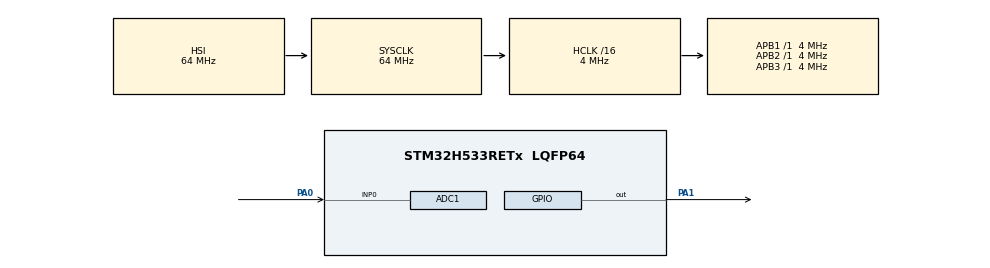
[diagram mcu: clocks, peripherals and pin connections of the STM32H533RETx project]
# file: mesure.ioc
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ADC1.Channel-0\#ChannelRegularConversion=ADC_CHANNEL_0
ADC1.ContinuousConvMode=ENABLE
ADC1.DMAContinuousRequests=ENABLE
ADC1.EOCSelection=ADC_EOC_SEQ_CONV
ADC1.MonitoredBy-0\#ChannelRegularConversion=__NULL
ADC1.NbrOfConversionFlag=1
ADC1.OffsetNumber-0\#ChannelRegularConversion=ADC_OFFSET_NONE
ADC1.Rank-0\#ChannelRegularConversion=1
ADC1.SamplingTime-0\#ChannelRegularConversion=ADC_SAMPLETIME_640CYCLES_5
ADC1.master=1
BOOTPATH.BootPathName=LEGACY
BOOTPATH.UserSelectedBootPath=LEGACY
CORTEX_M33_NS.userName=CORTEX_M33
GPDMA1.CIRCULARMODE_GPDMACH7=ENABLE
GPDMA1.DESTDATAWIDTH_GPDMACH7=DMA_DEST_DATAWIDTH_HALFWORD
GPDMA1.DESTINC_GPDMACH7=DMA_DINC_INCREMENTED
GPDMA1.IPHANDLE_GPDMACH7-SIMPLEREQUEST_GPDMACH7=__NULL
GPDMA1.REQUEST_GPDMACH7=GPDMA1_REQUEST_ADC1
GPDMA1.SRCDATAWIDTH_GPDMACH7=DMA_SRC_DATAWIDTH_HALFWORD
Mcu.Family=STM32H5
Mcu.Name=STM32H533RETx
Mcu.Package=LQFP64
NVIC.GPDMA1_Channel7_IRQn=true\:0\:0\:false\:false\:true\:false\:true\:true
NVIC.PriorityGroup=NVIC_PRIORITYGROUP_4
PA0.Signal=ADCx_INP0
PA1.GPIO_Speed=GPIO_SPEED_FREQ_VERY_HIGH
PA1.Signal=GPIO_Output
ProjectManager.HeapSize=0x200
ProjectManager.StackSize=0x400
ProjectManager.TargetToolchain=STM32CubeIDE
RCC.ADCFreq_Value=4000000
RCC.AHBCLKDivider=RCC_SYSCLK_DIV16
RCC.AHBFreq_Value=4000000
RCC.APB1Freq_Value=4000000
RCC.APB1TimFreq_Value=4000000
RCC.APB2Freq_Value=4000000
RCC.APB2TimFreq_Value=4000000
RCC.APB3Freq_Value=4000000
RCC.CSI_VALUE=4000000
RCC.CortexFreq_Value=4000000
RCC.EPOD_VALUE=4000000
RCC.HCLKFreq_Value=4000000
RCC.HSE_VALUE=25000000
RCC.HSI48_VALUE=48000000
RCC.HSIDiv=RCC_HSI_DIV1
RCC.HSI_VALUE=64000000
RCC.LSE_VALUE=32768
RCC.LSIRC_VALUE=32000
RCC.PLL2FRACN=0
RCC.PLL3FRACN=0
RCC.PLLFRACN=0
RCC.PLLN=90
RCC.SYSCLKFreq_VALUE=64000000
RCC.USBFreq_Value=48000000
RCC.VCOOutputFreq_Value=360000000
SH.ADCx_INP0.0=ADC1_INP0,IN0-Single-Ended
VP_BOOTPATH_VS_BOOTPATH.Mode=BP_Activate
VP_CORTEX_M33_NS_VS_Hclk.Mode=Hclk_Mode
VP_GPDMA1_VS_GPDMACH7.Mode=SIMPLEREQUEST_GPDMACH7
VP_MEMORYMAP_VS_MEMORYMAP.Mode=CurAppReg
VP_PWR_VS_LPOM.Mode=PowerOptimisation
VP_PWR_VS_SECSignals.Mode=Security/Privilege
board=NUCLEO-H533RE

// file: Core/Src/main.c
/* USER CODE BEGIN Header */
/**
  ******************************************************************************
  * @file           : main.c
  * @brief          : Main program body
  ******************************************************************************
  * @attention
  *
  * Copyright (c) 2025 STMicroelectronics.
  * All rights reserved.
  *
  * This software is licensed under terms that can be found in the LICENSE file
  * in the root directory of this software component.
  * If no LICENSE file comes with this software, it is provided AS-IS.
  *
  ******************************************************************************
  */
/* USER CODE END Header */
#include "main.h"

ADC_HandleTypeDef hadc1;
DMA_NodeTypeDef Node_GPDMA1_Channel7;
DMA_QListTypeDef List_GPDMA1_Channel7;
DMA_HandleTypeDef handle_GPDMA1_Channel7;

void SystemClock_Config(void);
static void MX_GPIO_Init(void);
static void MX_GPDMA1_Init(void);
static void MX_ADC1_Init(void);

/* USER CODE BEGIN 0 */
uint32_t raw;

void HAL_ADC_ConvCpltCallback(ADC_HandleTypeDef *hadc){
	HAL_GPIO_TogglePin(GPIOA, GPIO_PIN_1);
}

/* USER CODE END 0 */

int main(void)
{

  /* MCU Configuration--------------------------------------------------------*/

  /* Reset of all peripherals, Initializes the Flash interface and the Systick. */
  HAL_Init();

  /* Configure the system clock */
  SystemClock_Config();

  /* Initialize all configured peripherals */
  MX_GPIO_Init();
  MX_GPDMA1_Init();
  MX_ADC1_Init();
  /* USER CODE BEGIN 2 */
  HAL_ADC_Start_DMA(&hadc1, &raw, 1);

  /* USER CODE END 2 */

  /* Infinite loop */
  while (1)
  {

  }
}

void SystemClock_Config(void)
{
  RCC_OscInitTypeDef RCC_OscInitStruct = {0};
  RCC_ClkInitTypeDef RCC_ClkInitStruct = {0};

  /** Configure the main internal regulator output voltage
  */
  __HAL_PWR_VOLTAGESCALING_CONFIG(PWR_REGULATOR_VOLTAGE_SCALE3);

  while(!__HAL_PWR_GET_FLAG(PWR_FLAG_VOSRDY)) {}

  /** Initializes the RCC Oscillators according to the specified parameters
  * in the RCC_OscInitTypeDef structure.
  */
  RCC_OscInitStruct.OscillatorType = RCC_OSCILLATORTYPE_HSI;
  RCC_OscInitStruct.HSIState = RCC_HSI_ON;
  RCC_OscInitStruct.HSIDiv = RCC_HSI_DIV1;
  RCC_OscInitStruct.HSICalibrationValue = RCC_HSICALIBRATION_DEFAULT;
  RCC_OscInitStruct.PLL.PLLState = RCC_PLL_NONE;
  if (HAL_RCC_OscConfig(&RCC_OscInitStruct) != HAL_OK)
  {
    Error_Handler();
  }

  /** Initializes the CPU, AHB and APB buses clocks
  */
  RCC_ClkInitStruct.ClockType = RCC_CLOCKTYPE_HCLK|RCC_CLOCKTYPE_SYSCLK
                              |RCC_CLOCKTYPE_PCLK1|RCC_CLOCKTYPE_PCLK2
                              |RCC_CLOCKTYPE_PCLK3;
  RCC_ClkInitStruct.SYSCLKSource = RCC_SYSCLKSOURCE_HSI;
  RCC_ClkInitStruct.AHBCLKDivider = RCC_SYSCLK_DIV16;
  RCC_ClkInitStruct.APB1CLKDivider = RCC_HCLK_DIV1;
  RCC_ClkInitStruct.APB2CLKDivider = RCC_HCLK_DIV1;
  RCC_ClkInitStruct.APB3CLKDivider = RCC_HCLK_DIV1;

  if (HAL_RCC_ClockConfig(&RCC_ClkInitStruct, FLASH_LATENCY_3) != HAL_OK)
  {
    Error_Handler();
  }

  /** Configure the programming delay
  */
  __HAL_FLASH_SET_PROGRAM_DELAY(FLASH_PROGRAMMING_DELAY_1);
}

static void MX_ADC1_Init(void)
{

  ADC_ChannelConfTypeDef sConfig = {0};

  /** Common config
  */
  hadc1.Instance = ADC1;
  hadc1.Init.ClockPrescaler = ADC_CLOCK_ASYNC_DIV2;
  hadc1.Init.Resolution = ADC_RESOLUTION_12B;
  hadc1.Init.DataAlign = ADC_DATAALIGN_RIGHT;
  hadc1.Init.ScanConvMode = ADC_SCAN_DISABLE;
  hadc1.Init.EOCSelection = ADC_EOC_SEQ_CONV;
  hadc1.Init.LowPowerAutoWait = DISABLE;
  hadc1.Init.ContinuousConvMode = ENABLE;
  hadc1.Init.NbrOfConversion = 1;
  hadc1.Init.DiscontinuousConvMode = DISABLE;
  hadc1.Init.ExternalTrigConv = ADC_SOFTWARE_START;
  hadc1.Init.ExternalTrigConvEdge = ADC_EXTERNALTRIGCONVEDGE_NONE;
  hadc1.Init.DMAContinuousRequests = ENABLE;
  hadc1.Init.SamplingMode = ADC_SAMPLING_MODE_NORMAL;
  hadc1.Init.Overrun = ADC_OVR_DATA_PRESERVED;
  hadc1.Init.OversamplingMode = DISABLE;
  if (HAL_ADC_Init(&hadc1) != HAL_OK)
  {
    Error_Handler();
  }

  /** Configure Regular Channel
  */
  sConfig.Channel = ADC_CHANNEL_0;
  sConfig.Rank = ADC_REGULAR_RANK_1;
  sConfig.SamplingTime = ADC_SAMPLETIME_640CYCLES_5;
  sConfig.SingleDiff = ADC_SINGLE_ENDED;
  sConfig.OffsetNumber = ADC_OFFSET_NONE;
  sConfig.Offset = 0;
  if (HAL_ADC_ConfigChannel(&hadc1, &sConfig) != HAL_OK)
  {
    Error_Handler();
  }

}

static void MX_GPDMA1_Init(void)
{

  /* Peripheral clock enable */
  __HAL_RCC_GPDMA1_CLK_ENABLE();

  /* GPDMA1 interrupt Init */
    HAL_NVIC_SetPriority(GPDMA1_Channel7_IRQn, 0, 0);
    HAL_NVIC_EnableIRQ(GPDMA1_Channel7_IRQn);

}

static void MX_GPIO_Init(void)
{
  GPIO_InitTypeDef GPIO_InitStruct = {0};

  /* GPIO Ports Clock Enable */
  __HAL_RCC_GPIOA_CLK_ENABLE();

  /*Configure GPIO pin Output Level */
  HAL_GPIO_WritePin(GPIOA, GPIO_PIN_1, GPIO_PIN_RESET);

  /*Configure GPIO pin : PA1 */
  GPIO_InitStruct.Pin = GPIO_PIN_1;
  GPIO_InitStruct.Mode = GPIO_MODE_OUTPUT_PP;
  GPIO_InitStruct.Pull = GPIO_NOPULL;
  GPIO_InitStruct.Speed = GPIO_SPEED_FREQ_VERY_HIGH;
  HAL_GPIO_Init(GPIOA, &GPIO_InitStruct);

}

void Error_Handler(void)
{
  __disable_irq();
  while (1)
  {
  }
}
